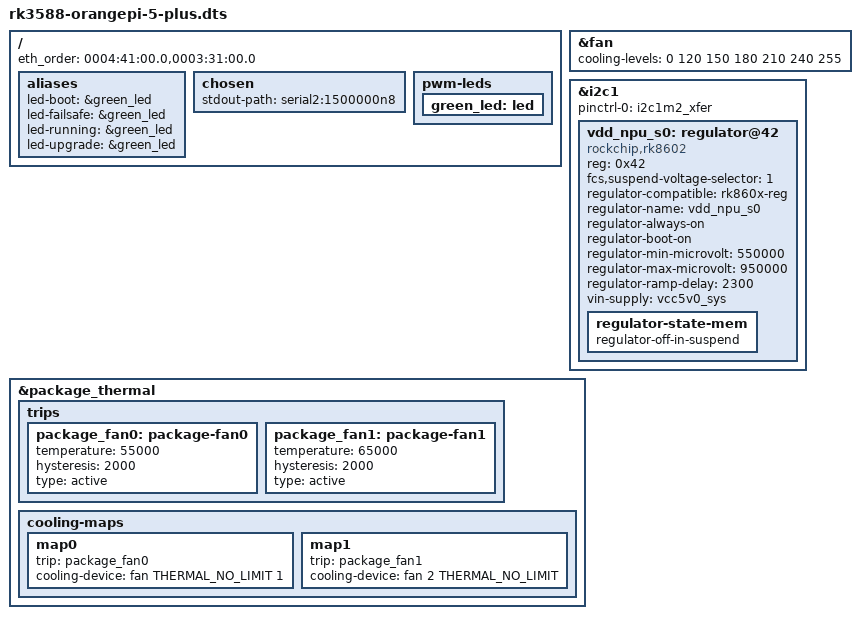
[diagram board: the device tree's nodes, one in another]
// SPDX-License-Identifier: (GPL-2.0+ OR MIT)

/dts-v1/;

#include <rockchip/rk3588-orangepi-5-plus.dts>

#define vdd_gpu_mem_s0 vdd_gpu_s0
#define vdd_npu_mem_s0 vdd_npu_s0
#define vdd_vdenc_mem_s0 vdd_vdenc_s0

#include "rk3588s-ip.dtsi"
#include "rk3588s-ip-supply.dtsi"

#include "rk3588-ramoops.dtsi"

/ {
	eth_order = "0004:41:00.0,0003:31:00.0";

	aliases {
		led-boot = &green_led;
		led-failsafe = &green_led;
		led-running = &green_led;
		led-upgrade = &green_led;
	};

	chosen {
		stdout-path = "serial2:1500000n8";
	};

	pwm-leds {
		green_led: led {
		};
	};

};

&fan {
	cooling-levels = <0 120 150 180 210 240 255>;
};

&i2c1 {
    pinctrl-names = "default";
    pinctrl-0 = <&i2c1m2_xfer>;
    status = "okay";

    vdd_npu_s0: regulator@42 {
        compatible = "rockchip,rk8602";
        reg = <0x42>;
        fcs,suspend-voltage-selector = <1>;
        regulator-compatible = "rk860x-reg";
        regulator-name = "vdd_npu_s0";
        regulator-always-on;
        regulator-boot-on;
        regulator-min-microvolt = <550000>;
        regulator-max-microvolt = <950000>;
        regulator-ramp-delay = <2300>;
        vin-supply = <&vcc5v0_sys>;

        regulator-state-mem {
            regulator-off-in-suspend;
        };
    };
};

&package_thermal {

	trips {
		package_fan0: package-fan0 {
			temperature = <55000>;
			hysteresis = <2000>;
			type = "active";
		};

		package_fan1: package-fan1 {
			temperature = <65000>;
			hysteresis = <2000>;
			type = "active";
		};
	};

	cooling-maps {
		map0 {
			trip = <&package_fan0>;
			cooling-device = <&fan THERMAL_NO_LIMIT 1>;
		};

		map1 {
			trip = <&package_fan1>;
			cooling-device = <&fan 2 THERMAL_NO_LIMIT>;
		};
	};
};
